# STM32L412 register map
File version: 1.9
CPU: CM4 r0p1, little endian, MPU, FPU, 4 interrupt priority bits
Registers are 32-bit, read-write, reset 0x0 unless marked. A register's access mark holds for its fields unless they carry their own. Offsets are from the block's base; [hi:lo] are bit positions; {n}, {i} and the like mark numbered series; 'fields as' and 'values as' point back to an identical list; <NAME> marks a mode.

## OPAMP — Operational amplifiers
Base 0x40007800
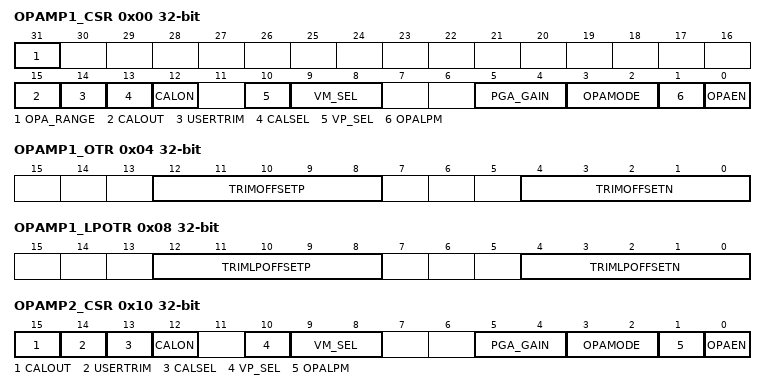
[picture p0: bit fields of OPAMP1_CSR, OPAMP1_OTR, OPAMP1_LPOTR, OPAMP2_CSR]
0x00 OPAMP1_CSR — OPAMP1 control/status register
  [31] OPA_RANGE — Operational amplifier power supply range for stability
    0=LOW (low range (VDDA < 2.4V); 1=HIGH (low range (VDDA >2.4V)
  [15] CALOUT — Operational amplifier calibration output
  [14] USERTRIM — allows to switch from AOP offset trimmed values to AOP offset
    0=Factory trim used; 1=User trim used
  [13] CALSEL — Calibration selection
    0=NMOS (0.2V applied to OPAMP inputs during calibration); 1=PMOS (VDDA-0.2V applied to OPAMP inputs during calibration")
  [12] CALON — Calibration mode enabled
    0=Disabled (Normal mode); 1=Enabled (Calibration mode)
  [10] VP_SEL — Non inverted input selection
    0=GPIO (GPIO connected to VINP); 1=DAC (DAC connected to VPINP)
  [9:8] VM_SEL — Inverting input selection
    0=GPIO (GPIO connectet to VINM); 1=LOW_LEAKAGE (Low leakage inputs connected (only available in certein BGA cases); 2=PGA_MODE (OPAMP in PGA mode)
  [5:4] PGA_GAIN — Operational amplifier Programmable amplifier gain value
    0=Gain2; 1=Gain4; 2=Gain8; 3=Gain16
  [3:2] OPAMODE — Operational amplifier PGA mode
    0=PGA_DISABLED (internal PGA diabled); 2=PGA_ENABLED (internal PGA enabled, gain programmed in PGA_GAIN); 3=FOLLOWER (internal follower)
  [1] OPALPM — Operational amplifier Low Power Mode
    0=NORMAL (OpAmp in normal mode); 1=LOW (OpAmp in low power mode)
  [0] OPAEN — Operational amplifier Enable
    0=Disabled (OpAmp disabled); 1=Enabled (OpAmp enabled)
0x04 OPAMP1_OTR — OPAMP1 offset trimming register in normal mode
  [12:8] TRIMOFFSETP — Trim for PMOS differential pairs
  [4:0] TRIMOFFSETN — Trim for NMOS differential pairs
0x08 OPAMP1_LPOTR — OPAMP1 offset trimming register in low-power mode
  [12:8] TRIMLPOFFSETP — Trim for PMOS differential pairs
  [4:0] TRIMLPOFFSETN — Trim for NMOS differential pairs
0x10 OPAMP2_CSR — OPAMP2 control/status register
  [15] CALOUT — Operational amplifier calibration output
  [14] USERTRIM — allows to switch from AOP offset trimmed values to AOP offset
    0=Factory trim used; 1=User trim used
  [13] CALSEL — Calibration selection
    values as OPAMP1_CSR.CALSEL
  [12] CALON — Calibration mode enabled
    0=Disabled (Normal mode); 1=Enabled (Calibration mode)
  [10] VP_SEL — Non inverted input selection
    values as OPAMP1_CSR.VP_SEL
  [9:8] VM_SEL — Inverting input selection
    values as OPAMP1_CSR.VM_SEL
  [5:4] PGA_GAIN — Operational amplifier Programmable amplifier gain value
    0=Gain2; 1=Gain4; 2=Gain8; 3=Gain16
  [3:2] OPAMODE — Operational amplifier PGA mode
    values as OPAMP1_CSR.OPAMODE
  [1] OPALPM — Operational amplifier Low Power Mode
    values as OPAMP1_CSR.OPALPM
  [0] OPAEN — Operational amplifier Enable
    0=Disabled (OpAmp disabled); 1=Enabled (OpAmp enabled)
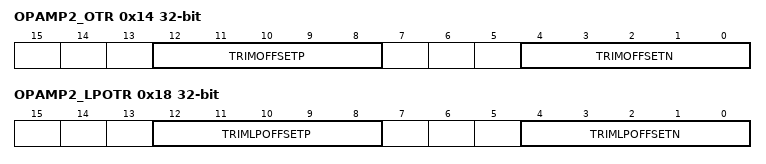
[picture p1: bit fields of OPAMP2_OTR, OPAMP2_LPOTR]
0x14 OPAMP2_OTR — OPAMP2 offset trimming register in normal mode
  fields as OPAMP1_OTR
0x18 OPAMP2_LPOTR — OPAMP2 offset trimming register in low-power mode
  fields as OPAMP1_LPOTR

## PWR — Power control
Base 0x40007000
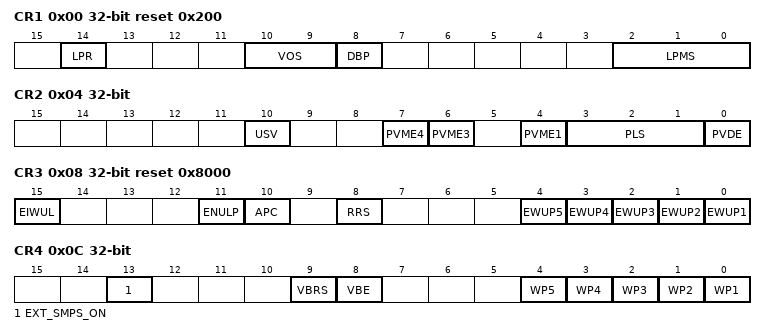
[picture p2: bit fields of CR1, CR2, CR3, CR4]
0x00 CR1 reset 0x200 — Power control register 1
  [14] LPR — Low-power run
  [10:9] VOS — Voltage scaling range selection
  [8] DBP — Disable backup domain write protection
  [2:0] LPMS — Low-power mode selection
0x04 CR2 — Power control register 2
  [10] USV — VDDUSB USB supply valid
  [7] PVME4 — Peripheral voltage monitoring 4 enable: VDDA vs. 2.2V
  [6] PVME3 — Peripheral voltage monitoring 3 enable: VDDA vs. 1.62V
  [4] PVME1 — Peripheral voltage monitoring 1 enable: VDDUSB vs. 1.2V
  [3:1] PLS — Power voltage detector level selection
  [0] PVDE — Power voltage detector enable
0x08 CR3 reset 0x8000 — Power control register 3
  [15] EIWUL — Enable internal wakeup line
  [11] ENULP — Enable ULP sampling of BOR and PVD
  [10] APC — Apply pull-up and pull-down configuration
  [8] RRS — SRAM2 retention in Standby mode
  [n-1] EWUP{n} (n=1..5) — Enable Wakeup pin WKUP{n}
0x0C CR4 — Power control register 4
  [13] EXT_SMPS_ON — External SMPS On
  [9] VBRS — VBAT battery charging resistor selection
  [8] VBE — VBAT battery charging enable
  [n-1] WP{n} (n=1..5) — Wakeup pin WKUP{n} polarity
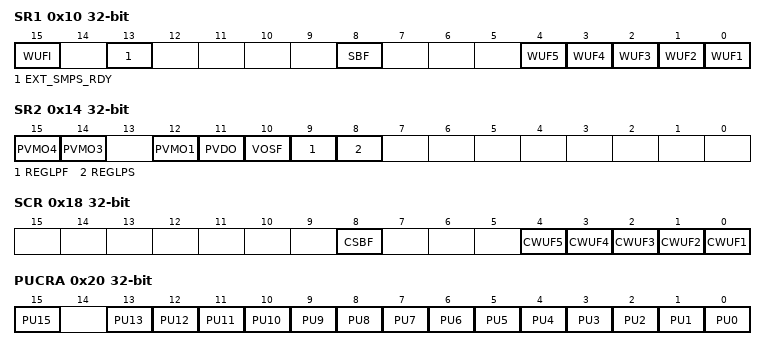
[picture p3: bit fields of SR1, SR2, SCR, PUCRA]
0x10 SR1 ro — Power status register 1
  [15] WUFI — Wakeup flag internal
  [13] EXT_SMPS_RDY — External SMPS Ready
  [8] SBF — Standby flag
  [n-1] WUF{n} (n=1..5) — Wakeup flag {n}
0x14 SR2 ro — Power status register 2
  [15] PVMO4 — Peripheral voltage monitoring output: VDDA vs. 2.2 V
  [14] PVMO3 — Peripheral voltage monitoring output: VDDA vs. 1.62 V
  [12] PVMO1 — Peripheral voltage monitoring output: VDDUSB vs. 1.2 V
  [11] PVDO — Power voltage detector output
  [10] VOSF — Voltage scaling flag
  [9] REGLPF — Low-power regulator flag
  [8] REGLPS — Low-power regulator started
0x18 SCR wo — Power status clear register
  [8] CSBF — Clear standby flag
  [n-1] CWUF{n} (n=1..5) — Clear wakeup flag {n}
0x20 PUCRA — Power Port A pull-up control register
  [15] PU15 — Port A pull-up bit y (y=0..15)
  [n] PU{n} (n=0..13) — Port A pull-up bit y (y=0..15)
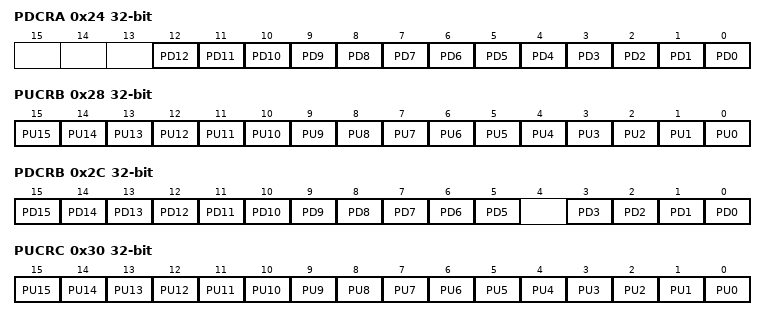
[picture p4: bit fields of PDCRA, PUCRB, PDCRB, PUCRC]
0x24 PDCRA — Power Port A pull-down control register
  [n] PD{n} (n=0..12) — Port A pull-down bit y (y=0..15)
0x28 PUCRB — Power Port B pull-up control register
  [n] PU{n} (n=0..15) — Port B pull-up bit y (y=0..15)
0x2C PDCRB — Power Port B pull-down control register
  [n] PD{n} (n=5..15) — Port B pull-down bit y (y=0..15)
  [n] PD{n} (n=0..3) — Port B pull-down bit y (y=0..15)
0x30 PUCRC — Power Port C pull-up control register
  [n] PU{n} (n=0..15) — Port C pull-up bit y (y=0..15)
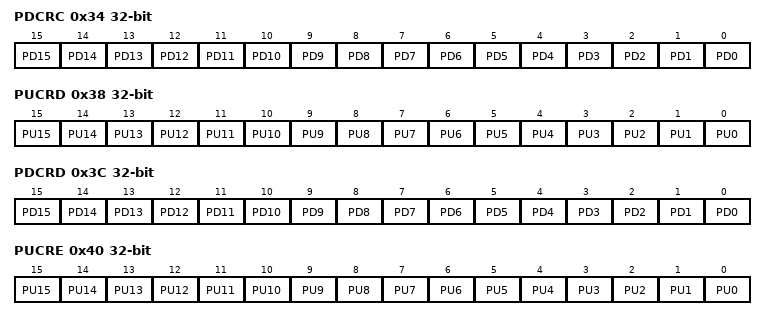
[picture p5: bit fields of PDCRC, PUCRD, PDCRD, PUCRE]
0x34 PDCRC — Power Port C pull-down control register
  [n] PD{n} (n=0..15) — Port C pull-down bit y (y=0..15)
0x38 PUCRD — Power Port D pull-up control register
  [n] PU{n} (n=0..15) — Port D pull-up bit y (y=0..15)
0x3C PDCRD — Power Port D pull-down control register
  [n] PD{n} (n=0..15) — Port D pull-down bit y (y=0..15)
0x40 PUCRE — Power Port E pull-up control register
  [n] PU{n} (n=0..15) — Port E pull-up bit y (y=0..15)
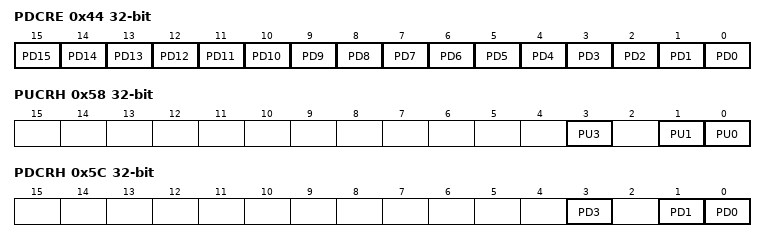
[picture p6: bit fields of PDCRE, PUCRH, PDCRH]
0x44 PDCRE — Power Port E pull-down control register
  [n] PD{n} (n=0..15) — Port E pull-down bit y (y=0..15)
0x58 PUCRH — Power Port H pull-up control register
  [3] PU3 — Port H pull-up bit y (y=0..1)
  [1] PU1 — Port H pull-up bit y (y=0..1)
  [0] PU0 — Port H pull-up bit y (y=0..1)
0x5C PDCRH — Power Port H pull-down control register
  [3] PD3 — Port H pull-down bit y (y=0..1)
  [1] PD1 — Port H pull-down bit y (y=0..1)
  [0] PD0 — Port H pull-down bit y (y=0..1)
